# AT91SAM9X35 register map
Vendor: Atmel; Series: SAM9X; File version: 20130207
Registers are 32-bit, read-write, reset 0x0 unless marked. A register's access mark holds for its fields unless they carry their own. Offsets are from the block's base; [hi:lo] are bit positions; {n}, {i} and the like mark numbered series; 'fields as' and 'values as' point back to an identical list.

## LCDC — LCD Controller
Base 0xF8038000; register names take the prefix LCDC_
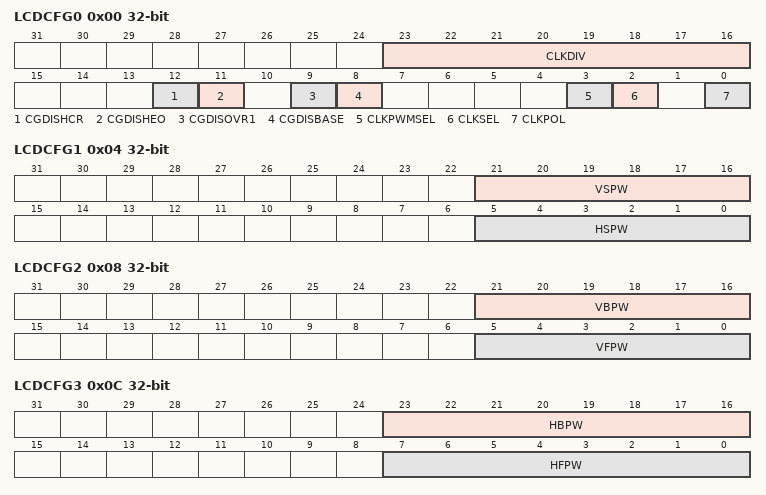
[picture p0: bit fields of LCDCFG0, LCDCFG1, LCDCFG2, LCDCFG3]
0x00 LCDCFG0 — LCD Controller Configuration Register 0
  [23:16] CLKDIV — LCD Controller Clock Divider
  [12] CGDISHCR — Clock Gating Disable Control for the Hardware Cursor Layer
  [11] CGDISHEO — Clock Gating Disable Control for the High End Overlay
  [9] CGDISOVR1 — Clock Gating Disable Control for the Overlay 1 Layer
  [8] CGDISBASE — Clock Gating Disable Control for the Base Layer
  [3] CLKPWMSEL — LCD Controller PWM Clock Source Selection
  [2] CLKSEL — LCD Controller Clock Source Selection
  [0] CLKPOL — LCD Controller Clock Polarity
0x04 LCDCFG1 — LCD Controller Configuration Register 1
  [21:16] VSPW — Vertical Synchronization Pulse Width
  [5:0] HSPW — Horizontal Synchronization Pulse Width
0x08 LCDCFG2 — LCD Controller Configuration Register 2
  [21:16] VBPW — Vertical Back Porch Width
  [5:0] VFPW — Vertical Front Porch Width
0x0C LCDCFG3 — LCD Controller Configuration Register 3
  [23:16] HBPW — Horizontal Back Porch Width
  [7:0] HFPW — Horizontal Front Porch Width
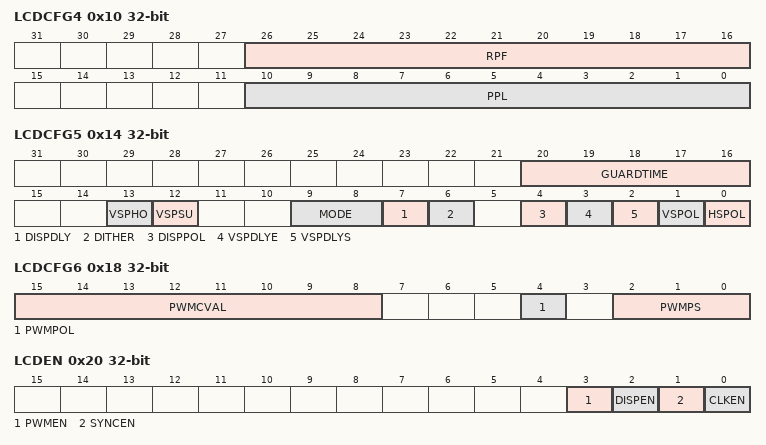
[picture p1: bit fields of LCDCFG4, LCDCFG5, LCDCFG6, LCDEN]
0x10 LCDCFG4 — LCD Controller Configuration Register 4
  [26:16] RPF — Number of Active Rows Per Frame
  [10:0] PPL — Number of Pixels Per Line
0x14 LCDCFG5 — LCD Controller Configuration Register 5
  [20:16] GUARDTIME — LCD DISPLAY Guard Time
  [13] VSPHO — LCD Controller Vertical Synchronization Pulse Hold Configuration
  [12] VSPSU — LCD Controller Vertical Synchronization Pulse Setup Configuration
  [9:8] MODE — LCD Controller Output Mode
    0=OUTPUT_12BPP (LCD output mode is set to 12 bits per pixel); 1=OUTPUT_16BPP (LCD output mode is set to 16 bits per pixel); 2=OUTPUT_18BPP (LCD output mode is set to 18 bits per pixel); 3=OUTPUT_24BPP (LCD output mode is set to 24 bits per pixel)
  [7] DISPDLY — LCD Controller Display Power Signal Synchronization
  [6] DITHER — LCD Controller Dithering
  [4] DISPPOL — Display Signal Polarity
  [3] VSPDLYE — Vertical Synchronization Pulse End
  [2] VSPDLYS — Vertical Synchronization Pulse Start
  [1] VSPOL — Vertical Synchronization Pulse Polarity
  [0] HSPOL — Horizontal Synchronization Pulse Polarity
0x18 LCDCFG6 — LCD Controller Configuration Register 6
  [15:8] PWMCVAL — LCD Controller PWM Compare Value
  [4] PWMPOL — LCD Controller PWM Signal Polarity
  [2:0] PWMPS — PWM Clock Prescaler
0x20 LCDEN wo reset not defined — LCD Controller Enable Register
  [3] PWMEN — LCD Controller Pulse Width Modulation Enable
  [2] DISPEN — LCD Controller DISP Signal Enable
  [1] SYNCEN — LCD Controller Horizontal and Vertical Synchronization Enable
  [0] CLKEN — LCD Controller Pixel Clock Enable
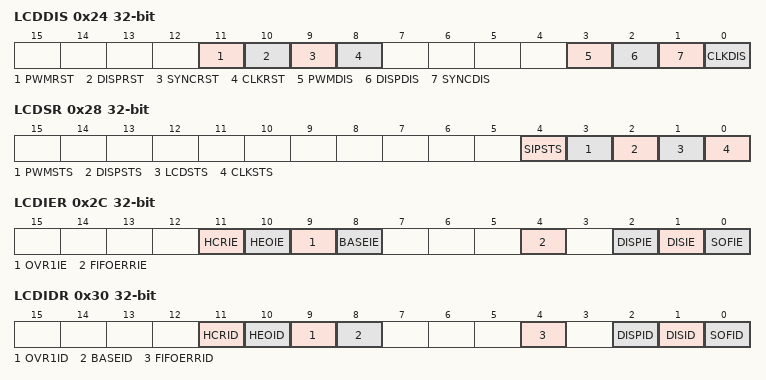
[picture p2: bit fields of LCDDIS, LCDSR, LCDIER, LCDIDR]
0x24 LCDDIS wo reset not defined — LCD Controller Disable Register
  [11] PWMRST — LCD Controller PWM Reset
  [10] DISPRST — LCD Controller DISP Signal Reset
  [9] SYNCRST — LCD Controller Horizontal and Vertical Synchronization Reset
  [8] CLKRST — LCD Controller Clock Reset
  [3] PWMDIS — LCD Controller Pulse Width Modulation Disable
  [2] DISPDIS — LCD Controller DISP Signal Disable
  [1] SYNCDIS — LCD Controller Horizontal and Vertical Synchronization Disable
  [0] CLKDIS — LCD Controller Pixel Clock Disable
0x28 LCDSR ro — LCD Controller Status Register
  [4] SIPSTS — Synchronization In Progress
  [3] PWMSTS — LCD Controller PWM Signal Status
  [2] DISPSTS — LCD Controller DISP Signal Status
  [1] LCDSTS — LCD Controller Synchronization status
  [0] CLKSTS — Clock Status
0x2C LCDIER wo reset not defined — LCD Controller Interrupt Enable Register
  [11] HCRIE — Hardware Cursor Interrupt Enable Register
  [10] HEOIE — High End Overlay Interrupt Enable Register
  [9] OVR1IE — Overlay 1 Interrupt Enable Register
  [8] BASEIE — Base Layer Interrupt Enable Register
  [4] FIFOERRIE — Output FIFO Error Interrupt Enable Register
  [2] DISPIE — Power UP/Down Sequence Terminated Interrupt Enable Register
  [1] DISIE — LCD Disable Interrupt Enable Register
  [0] SOFIE — Start of Frame Interrupt Enable Register
0x30 LCDIDR wo reset not defined — LCD Controller Interrupt Disable Register
  [11] HCRID — Hardware Cursor Interrupt Disable Register
  [10] HEOID — High End Overlay Interrupt Disable Register
  [9] OVR1ID — Overlay 1 Interrupt Disable Register
  [8] BASEID — Base Layer Interrupt Disable Register
  [4] FIFOERRID — Output FIFO Error Interrupt Disable Register
  [2] DISPID — Power UP/Down Sequence Terminated Interrupt Disable Register
  [1] DISID — LCD Disable Interrupt Disable Register
  [0] SOFID — Start of Frame Interrupt Disable Register
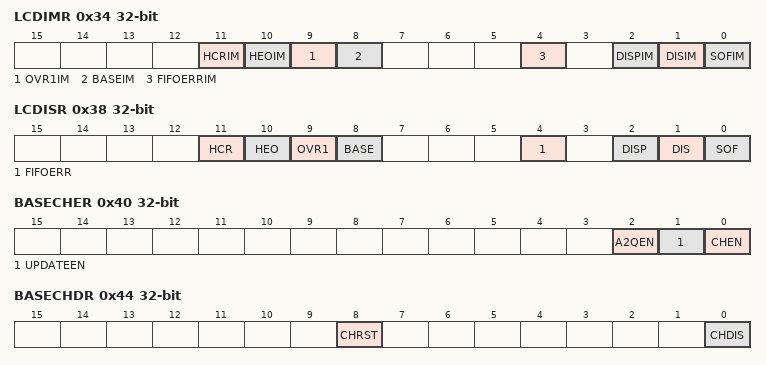
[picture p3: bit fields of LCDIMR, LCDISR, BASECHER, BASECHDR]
0x34 LCDIMR ro — LCD Controller Interrupt Mask Register
  [11] HCRIM — Hardware Cursor Interrupt Mask Register
  [10] HEOIM — High End Overlay Interrupt Mask Register
  [9] OVR1IM — Overlay 1 Interrupt Mask Register
  [8] BASEIM — Base Layer Interrupt Mask Register
  [4] FIFOERRIM — Output FIFO Error Interrupt Mask Register
  [2] DISPIM — Power UP/Down Sequence Terminated Interrupt Mask Register
  [1] DISIM — LCD Disable Interrupt Mask Register
  [0] SOFIM — Start of Frame Interrupt Mask Register
0x38 LCDISR ro — LCD Controller Interrupt Status Register
  [11] HCR — Hardware Cursor Raw Interrupt Status Register
  [10] HEO — High End Overlay Raw Interrupt Status Register
  [9] OVR1 — Overlay 1 Raw Interrupt Status Register
  [8] BASE — Base Layer Raw Interrupt Status Register
  [4] FIFOERR — Output FIFO Error
  [2] DISP — Power-up/Power-down Sequence Terminated Interrupt Status Register
  [1] DIS — LCD Disable Interrupt Status Register
  [0] SOF — Start of Frame Interrupt Status Register
0x40 BASECHER wo — Base Layer Channel Enable Register
  [2] A2QEN — Add Head Pointer Enable Register
  [1] UPDATEEN — Update Overlay Attributes Enable Register
  [0] CHEN — Channel Enable Register
0x44 BASECHDR wo — Base Layer Channel Disable Register
  [8] CHRST — Channel Reset Register
  [0] CHDIS — Channel Disable Register
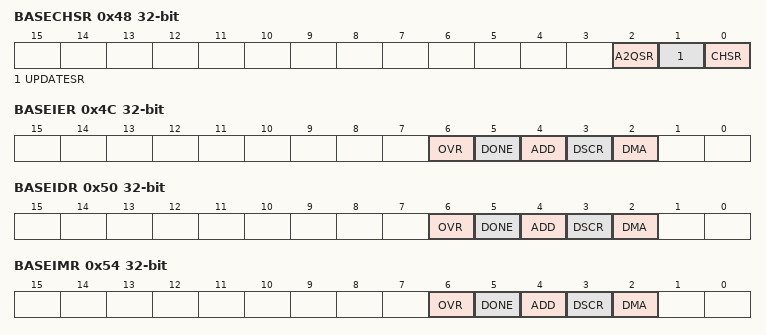
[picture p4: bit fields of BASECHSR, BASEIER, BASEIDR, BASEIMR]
0x48 BASECHSR ro — Base Layer Channel Status Register
  [2] A2QSR — Add To Queue Pending Register
  [1] UPDATESR — Update Overlay Attributes In Progress
  [0] CHSR — Channel Status Register
0x4C BASEIER wo — Base Layer Interrupt Enable Register
  [6] OVR — Overflow Interrupt Enable Register
  [5] DONE — End of List Interrupt Enable Register
  [4] ADD — Head Descriptor Loaded Interrupt Enable Register
  [3] DSCR — Descriptor Loaded Interrupt Enable Register
  [2] DMA — End of DMA Transfer Interrupt Enable Register
0x50 BASEIDR wo — Base Layer Interrupt Disabled Register
  [6] OVR — Overflow Interrupt Disable Register
  [5] DONE — End of List Interrupt Disable Register
  [4] ADD — Head Descriptor Loaded Interrupt Disable Register
  [3] DSCR — Descriptor Loaded Interrupt Disable Register
  [2] DMA — End of DMA Transfer Interrupt Disable Register
0x54 BASEIMR ro — Base Layer Interrupt Mask Register
  [6] OVR — Overflow Interrupt Mask Register
  [5] DONE — End of List Interrupt Mask Register
  [4] ADD — Head Descriptor Loaded Interrupt Mask Register
  [3] DSCR — Descriptor Loaded Interrupt Mask Register
  [2] DMA — End of DMA Transfer Interrupt Mask Register
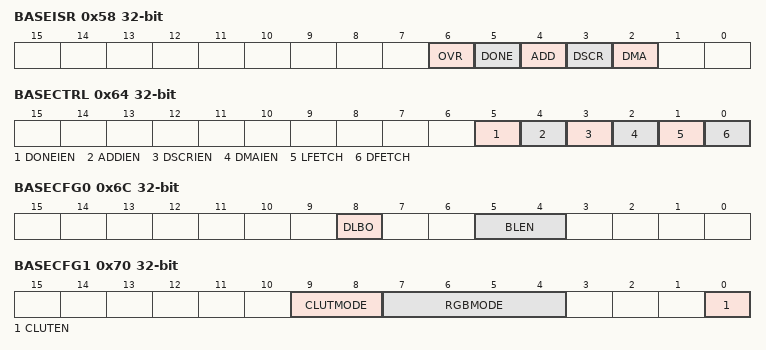
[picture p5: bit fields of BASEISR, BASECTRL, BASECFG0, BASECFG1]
0x58 BASEISR ro — Base Layer Interrupt status Register
  [6] OVR — Overflow Detected
  [5] DONE — End of List Detected
  [4] ADD — Head Descriptor Loaded
  [3] DSCR — DMA Descriptor Loaded
  [2] DMA — End of DMA Transfer
0x5C BASEHEAD — Base Layer DMA Head Register
  [31:2] HEAD — DMA Head Pointer
0x60 BASEADDR — Base Layer DMA Address Register
  [31:0] ADDR — DMA Transfer Start Address
0x64 BASECTRL — Base Layer DMA Control Register
  [5] DONEIEN — End of List Interrupt Enable
  [4] ADDIEN — Add Head Descriptor to Queue Interrupt Enable
  [3] DSCRIEN — Descriptor Loaded Interrupt Enable
  [2] DMAIEN — End of DMA Transfer Interrupt Enable
  [1] LFETCH — Lookup Table Fetch Enable
  [0] DFETCH — Transfer Descriptor Fetch Enable
0x68 BASENEXT — Base Layer DMA Next Register
  [31:0] NEXT — DMA Descriptor Next Address
0x6C BASECFG0 — Base Layer Configuration Register 0
  [8] DLBO — Defined Length Burst Only For Channel Bus Transaction.
  [5:4] BLEN — AHB Burst Length
    0=AHB_SINGLE (AHB Access is started as soon as there is enough space in the FIFO to store one 32-bit data. SINGLE, INCR, INCR4, INCR8 and INCR16 bursts can be used. INCR is used for a burst of 2 and 3 beats.); 1=AHB_INCR4 (AHB Access is started as soon as there is enough space in the FIFO to store a total amount of four 32-bit data. An AHB INCR4 Burst is preferred. SINGLE, INCR and INCR4 bursts can be used. INCR is used for a burst of 2 and 3 beats.); 2=AHB_INCR8 (AHB Access is started as soon as there is enough space in the FIFO to store a total amount of eight 32-bit data. An AHB INCR8 Burst is preferred. SINGLE, INCR, INCR4 and INCR8 bursts can be used. INCR is used for a burst of 2 and 3 beats.); 3=AHB_INCR16 (AHB Access is started as soon as there is enough space in the FIFO to store a total amount of sixteen 32-bit data. An AHB INCR16 Burst is preferred. SINGLE, INCR, INCR4, INCR8 and INCR16 bursts can be used. INCR is used for a burst of 2 and 3 beats.)
0x70 BASECFG1 — Base Layer Configuration Register 1
  [9:8] CLUTMODE — Color Lookup Table Input Mode Selection
    0=1BPP (color lookup table mode set to 1 bit per pixel); 1=2BPP (color lookup table mode set to 2 bits per pixel); 2=4BPP (color lookup table mode set to 4 bits per pixel); 3=8BPP (color lookup table mode set to 8 bits per pixel)
  [7:4] RGBMODE — RGB Input Mode Selection
    0=12BPP_RGB_444; 1=16BPP_ARGB_4444; 2=16BPP_RGBA_4444; 3=16BPP_RGB_565; 4=16BPP_TRGB_1555; 5=18BPP_RGB_666; 6=18BPP_RGB_666_PACKED; 7=19BPP_TRGB_1666; 8=19BPP_TRGB_PACKED (19 bpp TRGB 1666 PACKED); 9=24BPP_RGB_888; 10=24BPP_RGB_888_PACKED; 11=25BPP_TRGB_1888; 12=32BPP_ARGB_8888; 13=32BPP_RGBA_8888
  [0] CLUTEN — Color Lookup Table Enable
0x74 BASECFG2 — Base Layer Configuration Register 2
  [31:0] XSTRIDE — Horizontal Stride
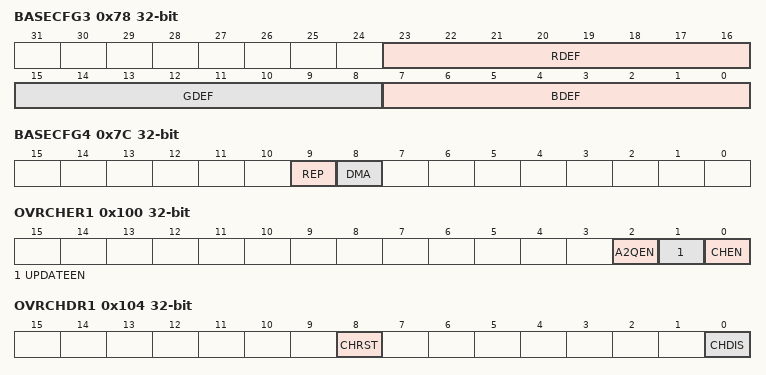
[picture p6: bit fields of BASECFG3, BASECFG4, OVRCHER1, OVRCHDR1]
0x78 BASECFG3 — Base Layer Configuration Register 3
  [23:16] RDEF — Red Default
  [15:8] GDEF — Green Default
  [7:0] BDEF — Blue Default
0x7C BASECFG4 — Base Layer Configuration Register 4
  [9] REP — Use Replication logic to expand RGB color to 24 bits
  [8] DMA — Use DMA Data Path
0x100 OVRCHER1 wo — Overlay 1 Channel Enable Register
  fields as BASECHER
0x104 OVRCHDR1 wo — Overlay 1 Channel Disable Register
  fields as BASECHDR
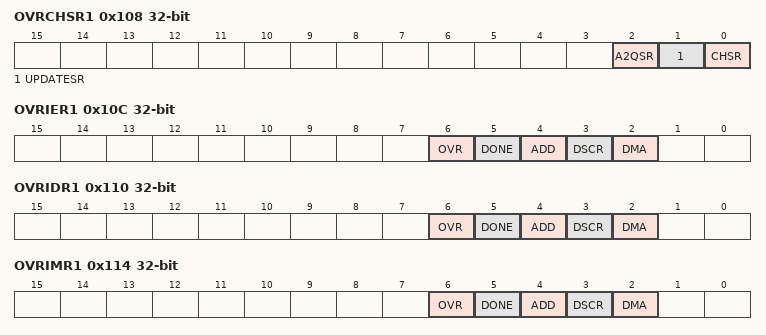
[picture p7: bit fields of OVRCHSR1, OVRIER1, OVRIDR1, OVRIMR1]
0x108 OVRCHSR1 ro — Overlay 1 Channel Status Register
  [2] A2QSR — Add to Queue Pending Register
  [1] UPDATESR — Update Overlay Attributes In Progress
  [0] CHSR — Channel Status Register
0x10C OVRIER1 wo — Overlay 1 Interrupt Enable Register
  fields as BASEIER
0x110 OVRIDR1 wo — Overlay 1 Interrupt Disable Register
  fields as BASEIDR
0x114 OVRIMR1 ro — Overlay 1 Interrupt Mask Register
  fields as BASEIMR
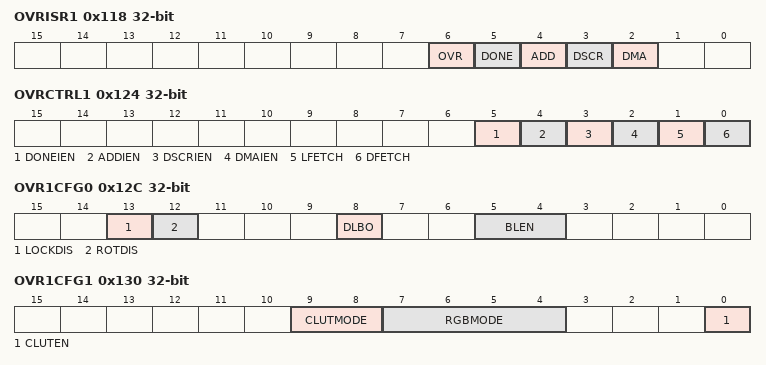
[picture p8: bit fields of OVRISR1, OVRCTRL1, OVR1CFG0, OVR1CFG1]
0x118 OVRISR1 ro — Overlay 1 Interrupt Status Register
  [6] OVR — Overflow Detected
  [5] DONE — End of List Detected Register
  [4] ADD — Head Descriptor Loaded
  [3] DSCR — DMA Descriptor Loaded
  [2] DMA — End of DMA Transfer
0x11C OVRHEAD1 — Overlay 1 DMA Head Register
  [31:2] HEAD — DMA Head Pointer
0x120 OVRADDR1 — Overlay 1 DMA Address Register
  [31:0] ADDR — DMA Transfer Overlay 1 Address
0x124 OVRCTRL1 — Overlay1 DMA Control Register
  fields as BASECTRL
0x128 OVRNEXT1 — Overlay1 DMA Next Register
  [31:0] NEXT — DMA Descriptor Next Address
0x12C OVR1CFG0 — Overlay 1 Configuration 0 Register
  [13] LOCKDIS — Hardware Rotation Lock Disable
  [12] ROTDIS — Hardware Rotation Optimization Disable
  [8] DLBO — Defined Length Burst Only for Channel Bus Transaction.
  [5:4] BLEN — AHB Burst Length
    0=AHB_SINGLE (AHB Access is started as soon as there is enough space in the FIFO to store one 32-bit data. SINGLE, INCR, INCR4, INCR8 and INCR16 bursts are preferred. INCR is used for a burst of 2 and 3 beats.); 1=AHB_INCR4 (AHB Access is started as soon as there is enough space in the FIFO to store a total amount of four 32-bit data. An AHB INCR4 Burst is preferred. SINGLE, INCR and INCR4 bursts can be used. INCR is used for a burst of 2 and 3 beats.); 2=AHB_INCR8 (AHB Access is started as soon as there is enough space in the FIFO to store a total amount of eight 32-bit data. An AHB INCR8 Burst is preferred. SINGLE, INCR, INCR4 and INCR8 bursts can be used. INCR is used for a burst of 2 and 3 beats.); 3=AHB_INCR16 (AHB Access is started as soon as there is enough space in the FIFO to store a total amount of sixteen 32-bit data. An AHB INCR16 Burst is preferred. SINGLE, INCR, INCR4, INCR8 and INCR16 bursts can be used. INCR is used for a burst of 2 and 3 beats.)
0x130 OVR1CFG1 — Overlay 1 Configuration 1 Register
  [9:8] CLUTMODE — Color Lookup table input mode selection
    values as BASECFG1.CLUTMODE
  [7:4] RGBMODE — RGB Input Mode Selection
    values as BASECFG1.RGBMODE
  [0] CLUTEN — Color Lookup Table Enable
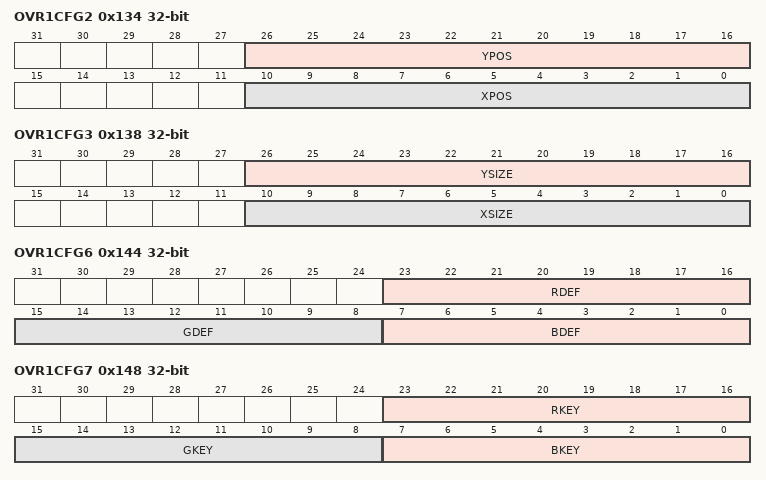
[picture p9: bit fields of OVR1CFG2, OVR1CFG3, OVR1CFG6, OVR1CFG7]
0x134 OVR1CFG2 — Overlay 1 Configuration 2 Register
  [26:16] YPOS — Vertical Window Position
  [10:0] XPOS — Horizontal Window Position
0x138 OVR1CFG3 — Overlay 1 Configuration 3 Register
  [26:16] YSIZE — Vertical Window Size
  [10:0] XSIZE — Horizontal Window Size
0x13C OVR1CFG4 — Overlay 1 Configuration 4 Register
  [31:0] XSTRIDE — Horizontal Stride
0x140 OVR1CFG5 — Overlay 1 Configuration 5 Register
  [31:0] PSTRIDE — Pixel Stride
0x144 OVR1CFG6 — Overlay 1 Configuration 6 Register
  fields as BASECFG3
0x148 OVR1CFG7 — Overlay 1 Configuration 7 Register
  [23:16] RKEY — Red Color Component Chroma Key
  [15:8] GKEY — Green Color Component Chroma Key
  [7:0] BKEY — Blue Color Component Chroma Key
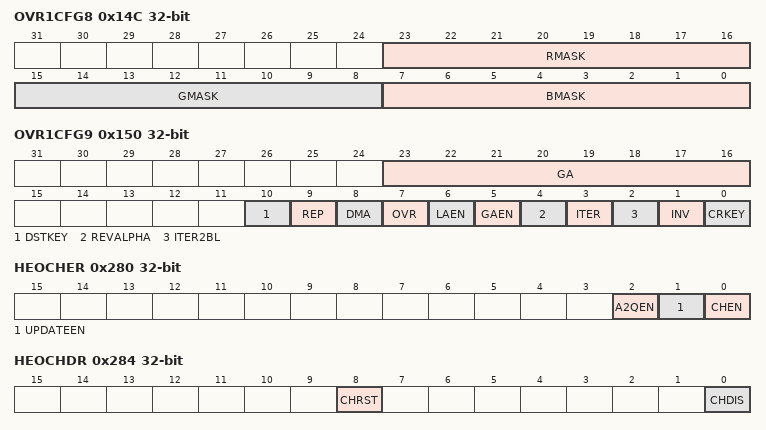
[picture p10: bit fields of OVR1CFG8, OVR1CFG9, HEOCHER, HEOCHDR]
0x14C OVR1CFG8 — Overlay 1 Configuration 8 Register
  [23:16] RMASK — Red Color Component Chroma Key Mask
  [15:8] GMASK — Green Color Component Chroma Key Mask
  [7:0] BMASK — Blue Color Component Chroma Key Mask
0x150 OVR1CFG9 — Overlay 1 Configuration 9 Register
  [23:16] GA — Blender Global Alpha
  [10] DSTKEY — Destination Chroma Keying
  [9] REP — Use Replication logic to expand RGB color to 24 bits
  [8] DMA — Blender DMA Layer Enable
  [7] OVR — Blender Overlay Layer Enable
  [6] LAEN — Blender Local Alpha Enable
  [5] GAEN — Blender Global Alpha Enable
  [4] REVALPHA — Blender Reverse Alpha
  [3] ITER — Blender Use Iterated Color
  [2] ITER2BL — Blender Iterated Color Enable
  [1] INV — Blender Inverted Blender Output Enable
  [0] CRKEY — Blender Chroma Key Enable
0x280 HEOCHER wo — High End Overlay Channel Enable Register
  fields as BASECHER
0x284 HEOCHDR wo — High End Overlay Channel Disable Register
  fields as BASECHDR
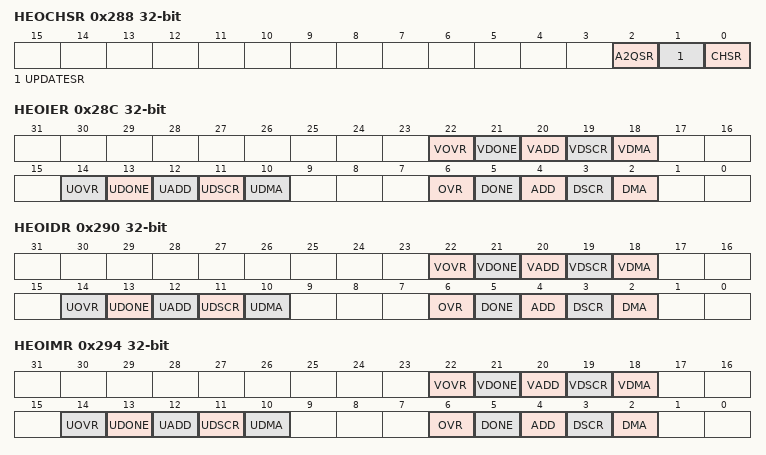
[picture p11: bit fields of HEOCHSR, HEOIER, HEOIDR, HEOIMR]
0x288 HEOCHSR ro — High End Overlay Channel Status Register
  fields as BASECHSR
0x28C HEOIER wo — High End Overlay Interrupt Enable Register
  [22] VOVR — Overflow for V Chrominance Interrupt Enable Register
  [21] VDONE — End of List for V Chrominance Interrupt Enable Register
  [20] VADD — Head Descriptor Loaded for V Chrominance Interrupt Enable Register
  [19] VDSCR — Descriptor Loaded for V Chrominance Interrupt Enable Register
  [18] VDMA — End of DMA for V Chrominance Transfer Interrupt Enable Register
  [14] UOVR — Overflow for U or UV Chrominance Interrupt Enable Register
  [13] UDONE — End of List for U or UV Chrominance Interrupt Enable Register
  [12] UADD — Head Descriptor Loaded for U or UV Chrominance Interrupt Enable Register
  [11] UDSCR — Descriptor Loaded for U or UV Chrominance Interrupt Enable Register
  [10] UDMA — End of DMA Transfer for U or UV Chrominance Interrupt Enable Register
  [6] OVR — Overflow Interrupt Enable Register
  [5] DONE — End of List Interrupt Enable Register
  [4] ADD — Head Descriptor Loaded Interrupt Enable Register
  [3] DSCR — Descriptor Loaded Interrupt Enable Register
  [2] DMA — End of DMA Transfer Interrupt Enable Register
0x290 HEOIDR wo — High End Overlay Interrupt Disable Register
  [22] VOVR — Overflow for V Chrominance Component Interrupt Disable Register
  [21] VDONE — End of List for V Chrominance Component Interrupt Disable Register
  [20] VADD — Head Descriptor Loaded for V Chrominance Component Interrupt Disable Register
  [19] VDSCR — Descriptor Loaded for V Chrominance Component Interrupt Disable Register
  [18] VDMA — End of DMA Transfer for V Chrominance Component Interrupt Disable Register
  [14] UOVR — Overflow Interrupt for U or UV Chrominance Component Disable Register
  [13] UDONE — End of List Interrupt for U or UV Chrominance Component Disable Register
  [12] UADD — Head Descriptor Loaded for U or UV Chrominance Component Interrupt Disable Register
  [11] UDSCR — Descriptor Loaded for U or UV Chrominance Component Interrupt Disable Register
  [10] UDMA — End of DMA Transfer for U or UV Chrominance Component Interrupt Disable Register
  [6] OVR — Overflow Interrupt Disable Register
  [5] DONE — End of List Interrupt Disable Register
  [4] ADD — Head Descriptor Loaded Interrupt Disable Register
  [3] DSCR — Descriptor Loaded Interrupt Disable Register
  [2] DMA — End of DMA Transfer Interrupt Disable Register
0x294 HEOIMR ro — High End Overlay Interrupt Mask Register
  [22] VOVR — Overflow for V Chrominance Interrupt Mask Register
  [21] VDONE — End of List for V Chrominance Component Mask Register
  [20] VADD — Head Descriptor Loaded for V Chrominance Component Mask Register
  [19] VDSCR — Descriptor Loaded for V Chrominance Component Interrupt Mask Register
  [18] VDMA — End of DMA Transfer for V Chrominance Component Interrupt Mask Register
  [14] UOVR — Overflow for U Chrominance Interrupt Mask Register
  [13] UDONE — End of List for U or UV Chrominance Component Mask Register
  [12] UADD — Head Descriptor Loaded for U or UV Chrominance Component Mask Register
  [11] UDSCR — Descriptor Loaded for U or UV Chrominance Component Interrupt Mask Register
  [10] UDMA — End of DMA Transfer for U or UV Chrominance Component Interrupt Mask Register
  [6] OVR — Overflow Interrupt Mask Register
  [5] DONE — End of List Interrupt Mask Register
  [4] ADD — Head Descriptor Loaded Interrupt Mask Register
  [3] DSCR — Descriptor Loaded Interrupt Mask Register
  [2] DMA — End of DMA Transfer Interrupt Mask Register
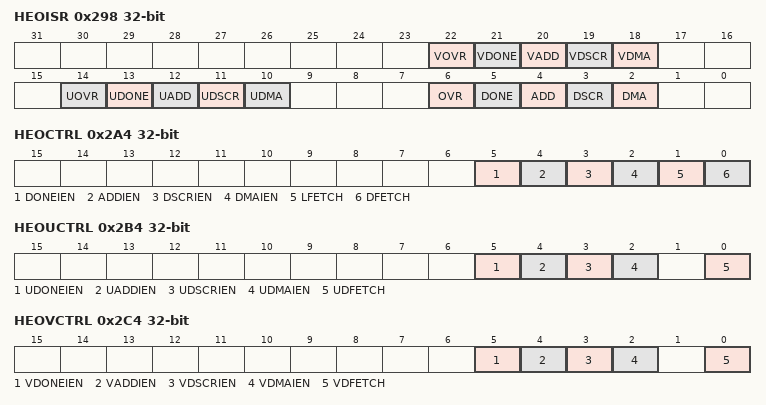
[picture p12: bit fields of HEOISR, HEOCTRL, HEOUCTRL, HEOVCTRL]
0x298 HEOISR ro — High End Overlay Interrupt Status Register
  [22] VOVR — Overflow Detected for V component
  [21] VDONE — End of List Detected for V component
  [20] VADD — Head Descriptor Loaded for V component
  [19] VDSCR — DMA Descriptor Loaded for V component
  [18] VDMA — End of DMA Transfer for V component
  [14] UOVR — Overflow Detected for U component
  [13] UDONE — End of List Detected for U component
  [12] UADD — Head Descriptor Loaded for U component
  [11] UDSCR — DMA Descriptor Loaded for U component
  [10] UDMA — End of DMA Transfer for U component
  [6] OVR — Overflow Detected
  [5] DONE — End of List Detected
  [4] ADD — Head Descriptor Loaded
  [3] DSCR — DMA Descriptor Loaded
  [2] DMA — End of DMA Transfer
0x29C HEOHEAD — High End Overlay DMA Head Register
  [31:2] HEAD — DMA Head Pointer
0x2A0 HEOADDR — High End Overlay DMA Address Register
  [31:0] ADDR — DMA Transfer start Address
0x2A4 HEOCTRL — High End Overlay DMA Control Register
  fields as BASECTRL
0x2A8 HEONEXT — High End Overlay DMA Next Register
  [31:0] NEXT — DMA Descriptor Next Address
0x2AC HEOUHEAD — High End Overlay U DMA Head Register
  [31:0] UHEAD — DMA Head Pointer
0x2B0 HEOUADDR — High End Overlay U DMA Address Register
  [31:0] UADDR — DMA Transfer Start Address for U or UV Chrominance
0x2B4 HEOUCTRL — High End Overlay U DMA Control Register
  [5] UDONEIEN — End of List Interrupt Enable
  [4] UADDIEN — Add Head Descriptor to Queue Interrupt Enable
  [3] UDSCRIEN — Descriptor Loaded Interrupt Enable
  [2] UDMAIEN — End of DMA Transfer Interrupt Enable
  [0] UDFETCH — Transfer Descriptor Fetch Enable
0x2B8 HEOUNEXT — High End Overlay U DMA Next Register
  [31:0] UNEXT — DMA Descriptor Next Address
0x2BC HEOVHEAD — High End Overlay V DMA Head Register
  [31:0] VHEAD — DMA Head Pointer
0x2C0 HEOVADDR — High End Overlay V DMA Address Register
  [31:0] VADDR — DMA Transfer Start Address for V Chrominance
0x2C4 HEOVCTRL — High End Overlay V DMA Control Register
  [5] VDONEIEN — End of List Interrupt Enable
  [4] VADDIEN — Add Head Descriptor to Queue Interrupt Enable
  [3] VDSCRIEN — Descriptor Loaded Interrupt Enable
  [2] VDMAIEN — End of DMA Transfer Interrupt Enable
  [0] VDFETCH — Transfer Descriptor Fetch Enable
0x2C8 HEOVNEXT — High End Overlay VDMA Next Register
  [31:0] VNEXT — DMA Descriptor Next Address
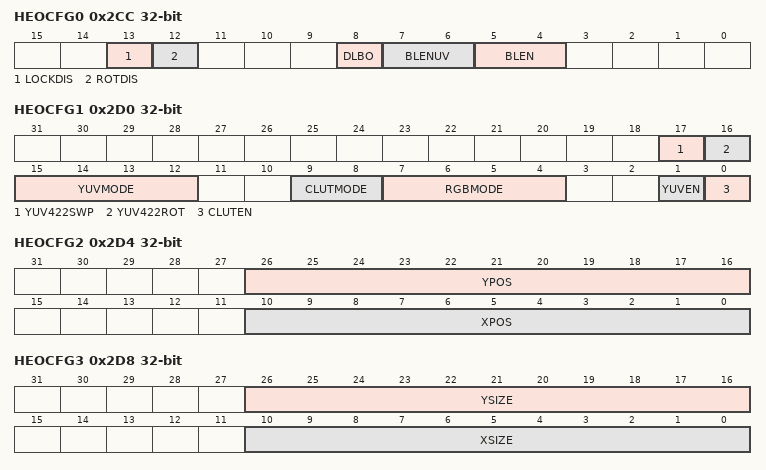
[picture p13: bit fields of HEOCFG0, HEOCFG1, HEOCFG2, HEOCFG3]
0x2CC HEOCFG0 — High End Overlay Configuration Register 0
  [13] LOCKDIS — Hardware Rotation Lock Disable
  [12] ROTDIS — Hardware Rotation Optimization Disable
  [8] DLBO — Defined Length Burst Only For Channel Bus Transaction
  [7:6] BLENUV — AHB Burst Length for U-V Channel
    0=AHB_SINGLE (AHB Access is started as soon as there is enough space in the FIFO to store one data. SINGLE, INCR, INCR4, INCR8 and INCR16 bursts can be used. INCR is used for a burst of 2 and 3 beats.); 1=AHB_INCR4 (AHB Access is started as soon as there is enough space in the FIFO to store a total amount of four 32-bit data. An AHB INCR4 Burst is preferred. SINGLE, INCR and INCR4 bursts can be used. INCR is used for a burst of 2 and 3 beats.); 2=AHB_INCR8 (AHB Access is started as soon as there is enough space in the FIFO to store a total amount of 8 data. An AHB INCR8 Burst is preferred. SINGLE, INCR, INCR4 and INCR8 bursts can be used. INCR is used for a burst of 2 and 3 beats.); 3=AHB_INCR16 (AHB Access is started as soon as there is enough space in the FIFO to store a total amount of sixteen 32-bit data. An AHB INCR16 Burst is preferred. SINGLE, INCR, INCR4, INCR8 and INCR16 bursts can be used. INCR is used for a burst of 2 and 3 beats.)
  [5:4] BLEN — AHB Burst Length
    values as BASECFG0.BLEN
0x2D0 HEOCFG1 — High End Overlay Configuration Register 1
  [17] YUV422SWP — YUV 4:2:2 SWAP
  [16] YUV422ROT — YUV 4:2:2 Rotation
  [15:12] YUVMODE — YUV input mode selection
    0=32BPP_AYCBCR (32 bpp AYCbCr 444); 1=16BPP_YCBCR_MODE0 (16 bpp Cr(n)Y(n+1)Cb(n)Y(n) 422); 2=16BPP_YCBCR_MODE1 (16 bpp Y(n+1)Cr(n)Y(n)Cb(n) 422); 3=16BPP_YCBCR_MODE2 (16 bpp Cb(n)Y(+1)Cr(n)Y(n) 422); 4=16BPP_YCBCR_MODE3 (16 bpp Y(n+1)Cb(n)Y(n)Cr(n) 422); 5=16BPP_YCBCR_SEMIPLANAR (16 bpp Semiplanar 422 YCbCr); 6=16BPP_YCBCR_PLANAR (16 bpp Planar 422 YCbCr); 7=12BPP_YCBCR_SEMIPLANAR (12 bpp Semiplanar 420 YCbCr); 8=12BPP_YCBCR_PLANAR (12 bpp Planar 420 YCbCr)
  [9:8] CLUTMODE — Color Lookup table input mode selection
    values as BASECFG1.CLUTMODE
  [7:4] RGBMODE — RGB input mode selection
    values as BASECFG1.RGBMODE
  [1] YUVEN — YUV Color Space Enable
  [0] CLUTEN — Color Lookup Table Enable
0x2D4 HEOCFG2 — High End Overlay Configuration Register 2
  fields as OVR1CFG2
0x2D8 HEOCFG3 — High End Overlay Configuration Register 3
  fields as OVR1CFG3
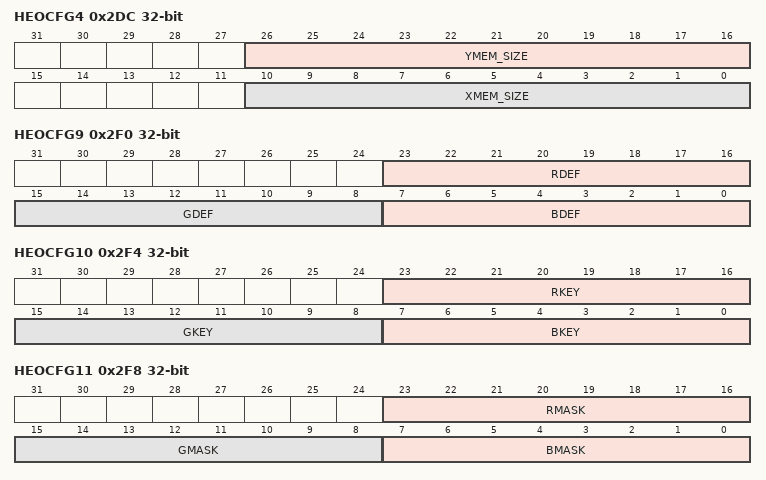
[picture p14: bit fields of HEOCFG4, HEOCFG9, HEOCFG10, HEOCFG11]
0x2DC HEOCFG4 — High End Overlay Configuration Register 4
  [26:16] YMEM_SIZE — Vertical image Size in Memory
  [10:0] XMEM_SIZE — Horizontal image Size in Memory
0x2E0 HEOCFG5 — High End Overlay Configuration Register 5
  [31:0] XSTRIDE — Horizontal Stride
0x2E4 HEOCFG6 — High End Overlay Configuration Register 6
  [31:0] PSTRIDE — Pixel Stride
0x2E8 HEOCFG7 — High End Overlay Configuration Register 7
  [31:0] UVXSTRIDE — UV Horizontal Stride
0x2EC HEOCFG8 — High End Overlay Configuration Register 8
  [31:0] UVPSTRIDE — UV Pixel Stride
0x2F0 HEOCFG9 — High End Overlay Configuration Register 9
  fields as BASECFG3
0x2F4 HEOCFG10 — High End Overlay Configuration Register 10
  fields as OVR1CFG7
0x2F8 HEOCFG11 — High End Overlay Configuration Register 11
  fields as OVR1CFG8
0x2FC HEOCFG12 — High End Overlay Configuration Register 12
  [23:16] GA — Blender Global Alpha
  [12] VIDPRI — Video Priority
  [10] DSTKEY — Destination Chroma Keying
  [9] REP — Use Replication logic to expand RGB color to 24 bits
  [8] DMA — Blender DMA Layer Enable
  [7] OVR — Blender Overlay Layer Enable
  [6] LAEN — Blender Local Alpha Enable
  [5] GAEN — Blender Global Alpha Enable
  [4] REVALPHA — Blender Reverse Alpha
  [3] ITER — Blender Use Iterated Color
  [2] ITER2BL — Blender Iterated Color Enable
  [1] INV — Blender Inverted Blender Output Enable
  [0] CRKEY — Blender Chroma Key Enable
0x300 HEOCFG13 — High End Overlay Configuration Register 13
  [31] SCALEN — Hardware Scaler Enable
  [28:16] YFACTOR — Vertical Scaling Factor
  [12:0] XFACTOR — Horizontal Scaling Factor
0x304 HEOCFG14 — High End Overlay Configuration Register 14
  [30] CSCYOFF — Color Space Conversion Offset
  [29:20] CSCRV — Color Space Conversion V coefficient for Red Component 1:2:7 format
  [19:10] CSCRU — Color Space Conversion U coefficient for Red Component 1:2:7 format
  [9:0] CSCRY — Color Space Conversion Y coefficient for Red Component 1:2:7 format
0x308 HEOCFG15 — High End Overlay Configuration Register 15
  [30] CSCUOFF — Color Space Conversion Offset
  [29:20] CSCGV — Color Space Conversion V coefficient for Green Component 1:2:7 format
  [19:10] CSCGU — Color Space Conversion U coefficient for Green Component 1:2:7 format
  [9:0] CSCGY — Color Space Conversion Y coefficient for Green Component 1:2:7 format
0x30C HEOCFG16 — High End Overlay Configuration Register 16
  [30] CSCVOFF — Color Space Conversion Offset
  [29:20] CSCBV — Color Space Conversion V coefficient for Blue Component 1:2:7 format
  [19:10] CSCBU — Color Space Conversion U coefficient for Blue Component 1:2:7 format
  [9:0] CSCBY — Color Space Conversion Y coefficient for Blue Component 1:2:7 format
0x340 HCRCHER wo — Hardware Cursor Channel Enable Register
  fields as BASECHER
0x344 HCRCHDR wo — Hardware Cursor Channel Disable Register
  fields as BASECHDR
0x348 HCRCHSR ro — Hardware Cursor Channel Status Register
  fields as BASECHSR
0x34C HCRIER wo — Hardware Cursor Interrupt Enable Register
  fields as BASEIER
0x350 HCRIDR wo — Hardware Cursor Interrupt Disable Register
  fields as BASEIDR
0x354 HCRIMR ro — Hardware Cursor Interrupt Mask Register
  fields as BASEIMR
0x358 HCRISR ro — Hardware Cursor Interrupt Status Register
  fields as BASEISR
0x35C HCRHEAD — Hardware Cursor DMA Head Register
  [31:2] HEAD — DMA Head Pointer
0x360 HCRADDR — Hardware cursor DMA Address Register
  [31:0] ADDR — DMA Transfer start address
0x364 HCRCTRL — Hardware Cursor DMA Control Register
  fields as BASECTRL
0x368 HCRNEXT — Hardware Cursor DMA NExt Register
  [31:0] NEXT — DMA Descriptor Next Address
0x36C HCRCFG0 — Hardware Cursor Configuration 0 Register
  [8] DLBO — Defined Length Burst Only for Channel Bus Transaction.
  [5:4] BLEN — AHB Burst Length
    0=AHB_SINGLE (AHB Access is started as soon as there is enough space in the FIFO to store one data. SINGLE, INCR, INCR4, INCR8 and INCR16 bursts can be used. INCR is used for a burst of 2 and 3 beats.); 1=AHB_INCR4 (AHB Access is started as soon as there is enough space in the FIFO to store a total amount of four 32-bit data. An AHB INCR4 Burst is preferred. SINGLE, INCR and INCR4 bursts can be used. INCR is used for a burst of 2 and 3 beats.); 2=AHB_INCR8 (AHB Access is started as soon as there is enough space in the FIFO to store a total amount of eight 32-bit data. An AHB INCR8 Burst is preferred. SINGLE, INCR, INCR4 and INCR8 bursts can be used. INCR is used for a burst of 2 and 3 beats.); 3=AHB_INCR16 (AHB Access is started as soon as there is enough space in the FIFO to store a total amount of sixteen 32-bit data. An AHB INCR16 Burst is preferred. SINGLE, INCR, INCR4, INCR8 and INCR16 bursts can be used. INCR is used for a burst of 2 and 3 beats.)
0x370 HCRCFG1 — Hardware Cursor Configuration 1 Register
  [9:8] CLUTMODE — Color Lookup table input mode selection
    values as BASECFG1.CLUTMODE
  [7:4] RGBMODE — RGB input mode selection
    values as BASECFG1.RGBMODE
  [0] CLUTEN — Color Lookup Table Enable
0x374 HCRCFG2 — Hardware Cursor Configuration 2 Register
  fields as OVR1CFG2
0x378 HCRCFG3 — Hardware Cursor Configuration 3 Register
  [22:16] YSIZE — Vertical Window Size
  [6:0] XSIZE — Horizontal Window Size
0x37C HCRCFG4 — Hardware Cursor Configuration 4 Register
  [31:0] XSTRIDE — Horizontal Stride
0x384 HCRCFG6 — Hardware Cursor Configuration 6 Register
  fields as BASECFG3
0x388 HCRCFG7 — Hardware Cursor Configuration 7 Register
  fields as OVR1CFG7
0x38C HCRCFG8 — Hardware Cursor Configuration 8 Register
  fields as OVR1CFG8
0x390 HCRCFG9 — Hardware Cursor Configuration 9 Register
  fields as OVR1CFG9
{0x400+4i} BASECLUT[{i}] (i=0..255) reset not defined
  [23:16] RCLUT — Red Color entry
  [15:8] GCLUT — Green Color entry
  [7:0] BCLUT — Blue Color entry
{0x800+4i} OVR1CLUT[{i}] (i=0..255) reset not defined — Overlay 1 CLUT Register
  [31:24] ACLUT — Alpha Color entry
  [23:16] RCLUT — Red Color entry
  [15:8] GCLUT — Green Color entry
  [7:0] BCLUT — Blue Color entry
{0x1000+4i} HEOCLUT[{i}] (i=0..255) reset not defined — High End Overlay CLUT Register
  fields as OVR1CLUT[0]
{0x1400+4i} HCRCLUT[{i}] (i=0..255) reset not defined — Hardware Cursor CLUT Register
  fields as OVR1CLUT[0]
0x1FEC ADDRSIZE ro reset not defined — Address Size Register
{0x1FF0+4i} IPNAME[{i}] (i=0..1) ro reset not defined — IP Name1 Register
0x1FF8 FEATURES ro reset not defined
0x1FFC VERSION ro reset not defined

## Notices in the file
SAM Software Package License
Copyright (c) 2013, Atmel Corporation
All rights reserved.
Redistribution and use in source and binary forms, with or without
modification, are permitted provided that the following condition is met:
- Redistributions of source code must retain the above copyright notice,
this list of conditions and the disclaimer below.
Atmel's name may not be used to endorse or promote products derived from
this software without specific prior written permission.
DISCLAIMER:  THIS SOFTWARE IS PROVIDED BY ATMEL "AS IS" AND ANY EXPRESS OR
IMPLIED WARRANTIES, INCLUDING, BUT NOT LIMITED TO, THE IMPLIED WARRANTIES OF
MERCHANTABILITY, FITNESS FOR A PARTICULAR PURPOSE AND NON-INFRINGEMENT ARE
DISCLAIMED. IN NO EVENT SHALL ATMEL BE LIABLE FOR ANY DIRECT, INDIRECT,
INCIDENTAL, SPECIAL, EXEMPLARY, OR CONSEQUENTIAL DAMAGES (INCLUDING, BUT NOT
LIMITED TO, PROCUREMENT OF SUBSTITUTE GOODS OR SERVICES; LOSS OF USE, DATA,
OR PROFITS; OR BUSINESS INTERRUPTION) HOWEVER CAUSED AND ON ANY THEORY OF
LIABILITY, WHETHER IN CONTRACT, STRICT LIABILITY, OR TORT (INCLUDING
NEGLIGENCE OR OTHERWISE) ARISING IN ANY WAY OUT OF THE USE OF THIS SOFTWARE,
EVEN IF ADVISED OF THE POSSIBILITY OF SUCH DAMAGE.
